# PY32F040Cxx register map
Vendor: Puya; Series: PY32F0; File version: 1.0.0
CPU: CM0+ r0p1, little endian, no MPU, no FPU, 4 interrupt priority bits
Registers are 32-bit, read-write, reset 0x0 unless marked. A register's access mark holds for its fields unless they carry their own. Offsets are from the block's base; [hi:lo] are bit positions; {n}, {i} and the like mark numbered series.

## TIM1 — Advanced timer
Base 0x40012C00
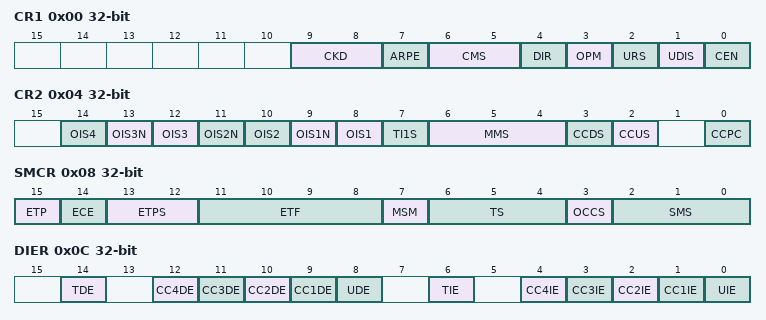
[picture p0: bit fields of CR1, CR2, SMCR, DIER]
0x00 CR1
  [9:8] CKD
    1=0; 2=1
  [7] ARPE
  [6:5] CMS
    1=0; 2=1
  [4] DIR
  [3] OPM
  [2] URS
  [1] UDIS
  [0] CEN
0x04 CR2
  [2n+6] OIS{n} (n=1..4)
  [13] OIS3N
  [11] OIS2N
  [9] OIS1N
  [7] TI1S
  [6:4] MMS
    1=0; 2=1; 4=2
  [3] CCDS
  [2] CCUS
  [0] CCPC
0x08 SMCR (reset mask 0xFFF7)
  [15] ETP
  [14] ECE
  [13:12] ETPS
    1=0; 2=1
  [11:8] ETF
    1=0; 2=1; 4=2; 8=3
  [7] MSM
  [6:4] TS
    1=0; 2=1; 4=2
  [3] OCCS
  [2:0] SMS
    1=0; 2=1; 4=2
0x0C DIER
  [14] TDE, [n+8] CC{n}DE (n=1..4), [8] UDE, [6] TIE, [n] CC{n}IE (n=1..4), [0] UIE
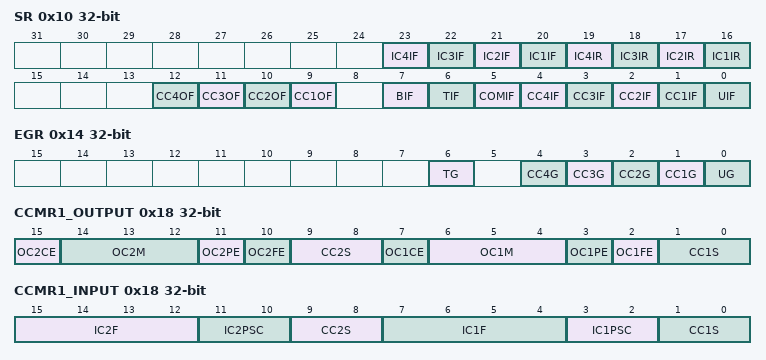
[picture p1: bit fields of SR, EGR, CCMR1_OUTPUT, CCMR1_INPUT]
0x10 SR (reset mask 0x1E5F)
  [23] IC4IF — desc IC3IF
  [22] IC3IF
  [21] IC2IF
  [20] IC1IF
  [19] IC4IR — desc IC3IR
  [18] IC3IR
  [17] IC2IR
  [16] IC1IR
  [n+8] CC{n}OF (n=1..4)
  [7] BIF
  [6] TIF
  [5] COMIF
  [n] CC{n}IF (n=1..4)
  [0] UIF
0x14 EGR wo
  [6] TG
  [4] CC4G
  [3] CC3G
  [2] CC2G
  [1] CC1G — Capture/Compare 1 Generation
  [0] UG
0x18 CCMR1_OUTPUT
  [15] OC2CE, [14:12] OC2M, [11] OC2PE, [10] OC2FE, [9:8] CC2S, [7] OC1CE, [6:4] OC1M, [3] OC1PE, [2] OC1FE, [1:0] CC1S
0x18 CCMR1_INPUT (alternate view of CCMR1_OUTPUT)
  [15:12] IC2F, [11:10] IC2PSC, [9:8] CC2S, [7:4] IC1F, [3:2] IC1PSC, [1:0] CC1S
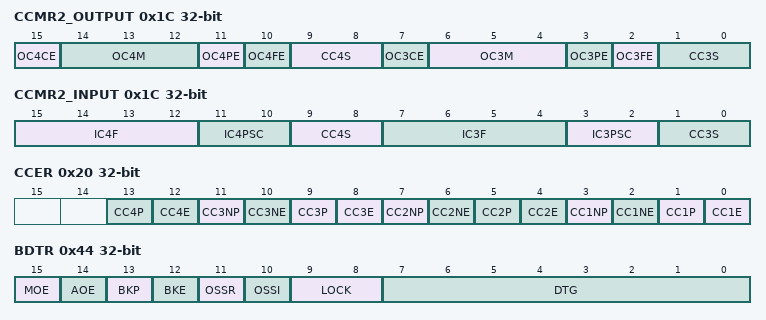
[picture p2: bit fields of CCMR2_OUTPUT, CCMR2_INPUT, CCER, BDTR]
0x1C CCMR2_OUTPUT
  [15] OC4CE, [14:12] OC4M, [11] OC4PE, [10] OC4FE, [9:8] CC4S, [7] OC3CE, [6:4] OC3M, [3] OC3PE, [2] OC3FE, [1:0] CC3S
0x1C CCMR2_INPUT (alternate view of CCMR2_OUTPUT)
  [15:12] IC4F, [11:10] IC4PSC, [9:8] CC4S, [7:4] IC3F, [3:2] IC3PSC, [1:0] CC3S
0x20 CCER (reset mask 0x3333)
  [4n-3] CC{n}P (n=1..4), [4n-4] CC{n}E (n=1..4), [11] CC3NP, [10] CC3NE, [7] CC2NP, [6] CC2NE, [3] CC1NP, [2] CC1NE
0x24 CNT (reset mask 0xFFFF)
0x28 PSC
  [15:0] PSC
0x2C ARR reset 0xFFFF
  [15:0] ARR
0x30 RCR reset 0xFFFF
  [7:0] REP
{0x30+4i} CCR{i} (i=1..4)
  [15:0] CCR{i}
0x44 BDTR
  [15] MOE
  [14] AOE
  [13] BKP
  [12] BKE
  [11] OSSR
  [10] OSSI
  [9:8] LOCK
    1=0; 2=1
  [7:0] DTG
    1=0; 2=1; 4=2; 8=3; 16=4; 32=5; 64=6; 128=7
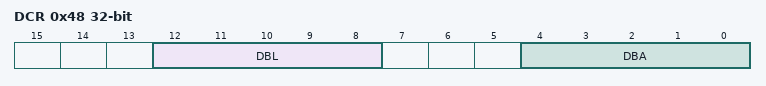
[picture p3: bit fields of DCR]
0x48 DCR
  [12:8] DBL
    1=0; 2=1; 4=2; 8=3; 16=4
  [4:0] DBA
    1=0; 2=1; 4=2; 8=3; 16=4
0x4C DMAR
  [15:0] DMAB

## TIM2 — desc TIM
Base 0x40000000
Registers as TIM1, without RCR, BDTR; these are added or differ:
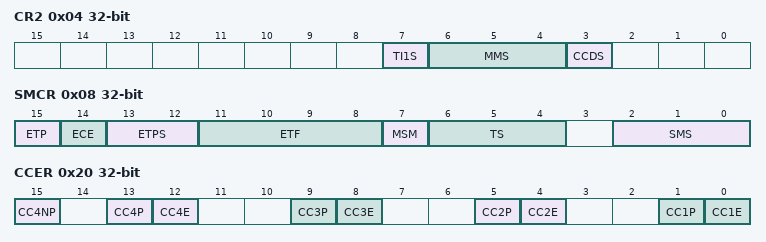
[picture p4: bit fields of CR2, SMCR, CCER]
0x04 CR2
  [7] TI1S
  [6:4] MMS
    1=0; 2=1; 4=2
  [3] CCDS
0x08 SMCR
  [15] ETP
  [14] ECE
  [13:12] ETPS
    1=0; 2=1
  [11:8] ETF
    1=0; 2=1; 4=2; 8=3
  [7] MSM
  [6:4] TS
    1=0; 2=1; 4=2
  [2:0] SMS
    1=0; 2=1; 4=2
0x20 CCER (reset mask 0x3333)
  [15] CC4NP, [4n-3] CC{n}P (n=1..4), [4n-4] CC{n}E (n=1..4)

## TIM3 — desc TIM
Base 0x40000400
Registers as TIM2; these are added or differ:
0x24 CNT
  [15:0] CNT

## TIM6 — desc TIM
Base 0x40001000
Same registers: TIM7 0x40001400
Registers as TIM3, without SMCR, CCMR1_OUTPUT, CCMR1_INPUT, CCMR2_OUTPUT, CCMR2_INPUT, CCER, CCR{n} (n=1..4), DCR, DMAR.

## TIM14 — General purpose timer
Base 0x40002000
Registers as TIM3, without CR2, SMCR, CCMR2_OUTPUT, CCMR2_INPUT, CCR{n} (n=2..4), DCR, DMAR; these are added or differ:
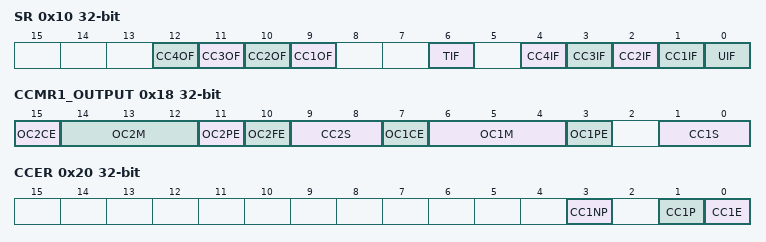
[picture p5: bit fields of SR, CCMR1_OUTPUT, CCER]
0x10 SR
  [n+8] CC{n}OF (n=1..4), [6] TIF, [n] CC{n}IF (n=1..4), [0] UIF
0x18 CCMR1_OUTPUT
  [15] OC2CE, [14:12] OC2M, [11] OC2PE, [10] OC2FE, [9:8] CC2S, [7] OC1CE, [6:4] OC1M, [3] OC1PE, [1:0] CC1S
0x20 CCER (reset mask 0x3333)
  [3] CC1NP, [1] CC1P, [0] CC1E
0x50 OR
  [1:0] TI1_RMP
    1=0; 2=1

## TIM15
Base 0x40014000
Registers as TIM1, without CCMR2_OUTPUT, CCMR2_INPUT, CCR3, CCR4; these are added or differ:
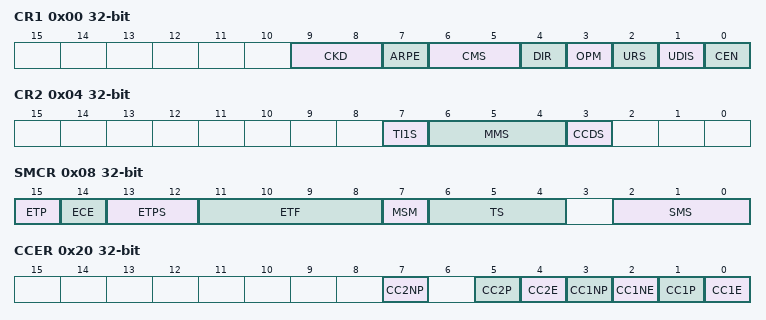
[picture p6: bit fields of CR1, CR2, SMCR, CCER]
0x00 CR1
  [9:8] CKD, [7] ARPE, [6:5] CMS, [4] DIR, [3] OPM, [2] URS, [1] UDIS, [0] CEN
0x04 CR2
  [7] TI1S, [6:4] MMS, [3] CCDS
0x08 SMCR
  [15] ETP, [14] ECE, [13:12] ETPS, [11:8] ETF, [7] MSM, [6:4] TS, [2:0] SMS
0x20 CCER (reset mask 0x3333)
  [7] CC2NP, [5] CC2P, [4] CC2E, [3] CC1NP, [2] CC1NE, [1] CC1P, [0] CC1E
0x24 CNT
  [15:0] CNT
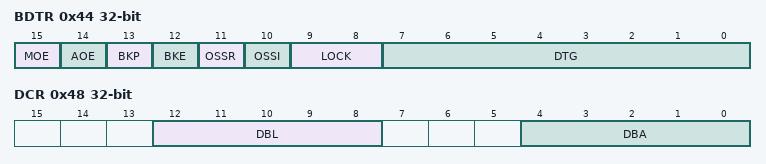
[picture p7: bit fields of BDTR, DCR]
0x44 BDTR
  [15] MOE, [14] AOE, [13] BKP, [12] BKE, [11] OSSR, [10] OSSI, [9:8] LOCK, [7:0] DTG
0x48 DCR
  [12:8] DBL, [4:0] DBA

## TIM16 — General purpose timer
Base 0x40014400
Same registers: TIM17 0x40014800
Registers as TIM1, without SMCR, CCMR2_OUTPUT, CCMR2_INPUT, CCR{n} (n=2..4); these are added or differ:
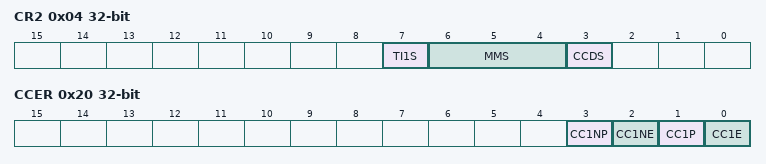
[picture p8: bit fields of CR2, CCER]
0x04 CR2
  [7] TI1S
  [6:4] MMS
    1=0; 2=1; 4=2
  [3] CCDS
0x20 CCER (reset mask 0x3333)
  [3] CC1NP, [2] CC1NE, [1] CC1P, [0] CC1E
0x24 CNT
  [15:0] CNT
